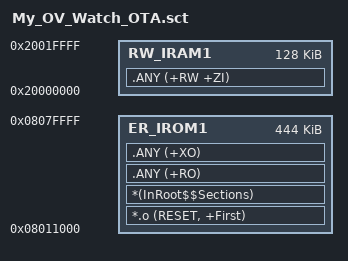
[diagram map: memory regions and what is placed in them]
; OTA 主应用固定链接布局。
; 使用显式 scatter 文件，避免 Keil Target 页的 ROM 地址被误改后静默回到 0x08000000。

LR_IROM1 0x08011000 0x0006F000  {
  ER_IROM1 0x08011000 0x0006F000  {
    *.o (RESET, +First)
    *(InRoot$$Sections)
    .ANY (+RO)
    .ANY (+XO)
  }
  RW_IRAM1 0x20000000 0x00020000  {
    .ANY (+RW +ZI)
  }
}
